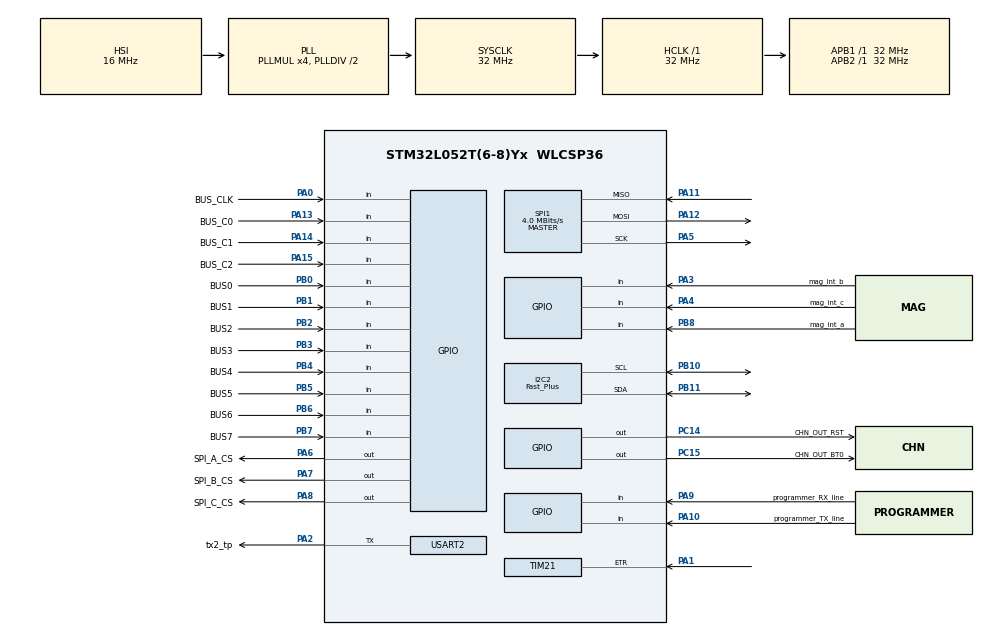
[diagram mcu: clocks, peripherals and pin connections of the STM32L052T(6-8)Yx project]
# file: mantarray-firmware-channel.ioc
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Mcu.Family=STM32L0
SPI1.VirtualType=VM_MASTER
PB10.Mode=I2C
PA14.GPIO_Label=BUS_C1
I2C2.Timing=0x00100413
PA0.GPIO_Label=BUS_CLK
I2C2.NoStretchMode=I2C_NOSTRETCH_ENABLE
PA11.Mode=Full_Duplex_Master
PB6.GPIO_Label=BUS6
PB0.GPIO_Label=BUS0
PA6.GPIO_Label=SPI_A_CS
PB11.Signal=I2C2_SDA
PC15-OSC32_OUT.GPIO_Label=CHN_OUT_BT0
RCC.SYSCLKSource=RCC_SYSCLKSOURCE_PLLCLK
ProjectManager.StackSize=0x400
PA15.GPIO_Label=BUS_C2
PA12.Signal=SPI1_MOSI
SPI1.CLKPolarity=SPI_POLARITY_HIGH
SPI1.Direction=SPI_DIRECTION_2LINES
RCC.HCLKFreq_Value=32000000
I2C2.I2C_Speed_Mode=I2C_Fast_Plus
RCC.APB2TimFreq_Value=32000000
PB6.Signal=GPIO_Input
SPI1.CalculateBaudRate=4.0 MBits/s
TIM22.Prescaler=31999
RCC.AHBFreq_Value=32000000
VP_TIM22_VS_ClockSourceINT.Mode=Internal
PB2.Signal=GPIO_Input
RCC.PLLMUL=RCC_PLLMUL_4
TIM22.AutoReloadPreload=TIM_AUTORELOAD_PRELOAD_ENABLE
PB1.GPIO_Label=BUS1
PA10.GPIO_Label=programmer_TX_line
PB7.Signal=GPIO_Input
PA8.Signal=GPIO_Output
PA0.Signal=GPIO_Input
PB7.GPIO_Label=BUS7
Mcu.Package=WLCSP36
PA6.Signal=GPIO_Output
PB1.Signal=GPIO_Input
PC14-OSC32_IN.PinState=GPIO_PIN_RESET
SH.S_TIM21_ETR.0=TIM21_ETR,ClockSourceETR_Mode2
PA2.GPIO_Label=tx2_tp
PA10.Signal=GPIO_Input
PA15.Signal=GPIO_Input
PB5.GPIO_Label=BUS5
RCC.APB1TimFreq_Value=32000000
PC14-OSC32_IN.GPIO_Label=CHN_OUT_RST
I2C2.GeneralCallMode=I2C_GENERALCALL_ENABLE
SPI1.BaudRatePrescaler=SPI_BAUDRATEPRESCALER_8
PA4.GPIO_Label=mag_int_c
RCC.HSI48_VALUE=48000000
PB4.Signal=GPIO_Input
PA3.Signal=GPIO_Input
PA5.Mode=Full_Duplex_Master
PB3.GPIO_Label=BUS3
RCC.MSI_VALUE=2097000
USART2.DMADisableonRxErrorParam=ADVFEATURE_DMA_DISABLEONRXERROR
VP_ADC_TempSens_Input.Mode=IN-TempSens
PA9.GPIO_Label=programmer_RX_line
VP_ADC_Vref_Input.Mode=IN-Vrefint
VP_TIM6_VS_ClockSourceINT.Mode=Enable_Timer
SPI1.CLKPhase=SPI_PHASE_2EDGE
PC14-OSC32_IN.Signal=GPIO_Output
TIM22.Period=9999
I2C2.OwnAddress=100
PA13.Signal=GPIO_Input
RCC.HSI16_VALUE=16000000
PB8.GPIO_Label=mag_int_a
PA8.GPIO_Label=SPI_C_CS
PB11.Mode=I2C
ProjectManager.TargetToolchain=STM32CubeIDE
NVIC.I2C2_IRQn=true\:0\:0\:false\:false\:false\:true\:true
PA9.Signal=GPIO_Input
RCC.LSE_VALUE=32768
PC15-OSC32_OUT.Signal=GPIO_Output
PA1.Signal=S_TIM21_ETR
PB10.Signal=I2C2_SCL
PA5.Signal=SPI1_SCK
board=custom
RCC.VCOOutputFreq_Value=64000000
RCC.APB2Freq_Value=32000000
PB4.GPIO_Label=BUS4
SPI1.Mode=SPI_MODE_MASTER
TIM21.AutoReloadPreload=TIM_AUTORELOAD_PRELOAD_ENABLE
NVIC.TIM21_IRQn=true\:0\:0\:false\:false\:true\:true\:true
Mcu.Name=STM32L052T(6-8)Yx
PA13.GPIO_Label=BUS_C0
PA2.Signal=USART2_TX
PB3.Signal=GPIO_Input
PA4.Signal=GPIO_Input
RCC.SYSCLKFreq_VALUE=32000000
PB5.Signal=GPIO_Input
PA7.GPIO_Label=SPI_B_CS
PA12.Mode=Full_Duplex_Master
USART2.VirtualMode-Half_duplex(single_wire_mode)=VM_ASYNC
PA11.Signal=SPI1_MISO
PA14.Signal=GPIO_Input
PB2.GPIO_Label=BUS2
ProjectManager.HeapSize=0x200
RCC.HSI_VALUE=16000000
PB8.Signal=GPIO_Input
PA2.Mode=Half_duplex(single_wire_mode)
RCC.APB1Freq_Value=32000000
USART2.Mode=MODE_TX
PB0.Signal=GPIO_Input
PA3.GPIO_Label=mag_int_b
PA7.Signal=GPIO_Output

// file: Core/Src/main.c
/* USER CODE BEGIN Header */
/**
  ******************************************************************************
  * @file           : main.c
  * @brief          : Main program body
  ******************************************************************************
  * @attention
  *
  * <h2><center>&copy; Copyright (c) 2021 STMicroelectronics.
  * All rights reserved.</center></h2>
  *
  * This software component is licensed by ST under BSD 3-Clause license,
  * the "License"; You may not use this file except in compliance with the
  * License. You may obtain a copy of the License at:
  *                        opensource.org/licenses/BSD-3-Clause
  *
  ******************************************************************************
  */
/* USER CODE END Header */
#include "main.h"
#include "adc.h"
#include "i2c.h"
#include "spi.h"
#include "tim.h"
#include "usart.h"
#include "gpio.h"

/* USER CODE BEGIN Includes */
#include "system.h"
/* USER CODE END Includes */

/* USER CODE BEGIN PV */

DMA_HandleTypeDef hdma_GPIOB_tx;
uint32_t address = 0x12345678;
uint16_t test1 = 0x1234;
uint8_t test2 = 0x12;

System my_sys;

/* USER CODE END PV */

void SystemClock_Config(void);

int main(void)
{

  /* MCU Configuration--------------------------------------------------------*/

  /* Reset of all peripherals, Initializes the Flash interface and the Systick. */
  HAL_Init();

  /* Configure the system clock */
  SystemClock_Config();

  /* Initialize all configured peripherals */
  MX_GPIO_Init();
  MX_I2C2_Init();
  MX_SPI1_Init();
  MX_ADC_Init();
  MX_USART2_UART_Init();
  MX_TIM6_Init();
  MX_TIM21_Init();
  MX_TIM22_Init();
  /* USER CODE BEGIN 2 */

  module_system_init(&my_sys, &hspi1, &hi2c2, &htim21);
  /* USER CODE END 2 */

  /* Infinite loop */
  /* USER CODE BEGIN WHILE */
  while (1)
  {
	  state_machine(&my_sys);
    /* USER CODE END WHILE */

  }
}

void SystemClock_Config(void)
{
  RCC_OscInitTypeDef RCC_OscInitStruct = {0};
  RCC_ClkInitTypeDef RCC_ClkInitStruct = {0};
  RCC_PeriphCLKInitTypeDef PeriphClkInit = {0};

  /** Configure the main internal regulator output voltage
  */
  __HAL_PWR_VOLTAGESCALING_CONFIG(PWR_REGULATOR_VOLTAGE_SCALE1);
  /** Initializes the RCC Oscillators according to the specified parameters
  * in the RCC_OscInitTypeDef structure.
  */
  RCC_OscInitStruct.OscillatorType = RCC_OSCILLATORTYPE_HSI|RCC_OSCILLATORTYPE_HSI48;
  RCC_OscInitStruct.HSIState = RCC_HSI_ON;
  RCC_OscInitStruct.HSICalibrationValue = RCC_HSICALIBRATION_DEFAULT;
  RCC_OscInitStruct.HSI48State = RCC_HSI48_ON;
  RCC_OscInitStruct.PLL.PLLState = RCC_PLL_ON;
  RCC_OscInitStruct.PLL.PLLSource = RCC_PLLSOURCE_HSI;
  RCC_OscInitStruct.PLL.PLLMUL = RCC_PLLMUL_4;
  RCC_OscInitStruct.PLL.PLLDIV = RCC_PLLDIV_2;
  if (HAL_RCC_OscConfig(&RCC_OscInitStruct) != HAL_OK)
  {
    Error_Handler();
  }
  /** Initializes the CPU, AHB and APB buses clocks
  */
  RCC_ClkInitStruct.ClockType = RCC_CLOCKTYPE_HCLK|RCC_CLOCKTYPE_SYSCLK
                              |RCC_CLOCKTYPE_PCLK1|RCC_CLOCKTYPE_PCLK2;
  RCC_ClkInitStruct.SYSCLKSource = RCC_SYSCLKSOURCE_PLLCLK;
  RCC_ClkInitStruct.AHBCLKDivider = RCC_SYSCLK_DIV1;
  RCC_ClkInitStruct.APB1CLKDivider = RCC_HCLK_DIV1;
  RCC_ClkInitStruct.APB2CLKDivider = RCC_HCLK_DIV1;

  if (HAL_RCC_ClockConfig(&RCC_ClkInitStruct, FLASH_LATENCY_1) != HAL_OK)
  {
    Error_Handler();
  }
  PeriphClkInit.PeriphClockSelection = RCC_PERIPHCLK_USART2;
  PeriphClkInit.Usart2ClockSelection = RCC_USART2CLKSOURCE_PCLK1;
  if (HAL_RCCEx_PeriphCLKConfig(&PeriphClkInit) != HAL_OK)
  {
    Error_Handler();
  }
}

void Error_Handler(void)
{
  __disable_irq();
  while (1)
  {
  }
}

/************************ (C) COPYRIGHT STMicroelectronics *****END OF FILE****/
